# cslr_dmac5501_001 register map
Vendor: Texas Instruments
Peripheral module from a debugger description file.
Registers are 16-bit, read-write, reset 0x0 unless marked. A register's access mark holds for its fields unless they carry their own. Offsets are as the file gives them; lines under a group give offsets from that group; [hi:lo] are bit positions; {n}, {i} and the like mark numbered series; 'fields as' and 'values as' point back to an identical list; <NAME> marks a mode.

## DMA — Direct Memory Access
0x00 DMAGCR access per field — Global Control Register
  [2] FREE rw — Emulation mode bit.
    0=A breakpoint suspends DMA transfers; 1=DMA transfers continue uninterrupted when a breakpoint occurs
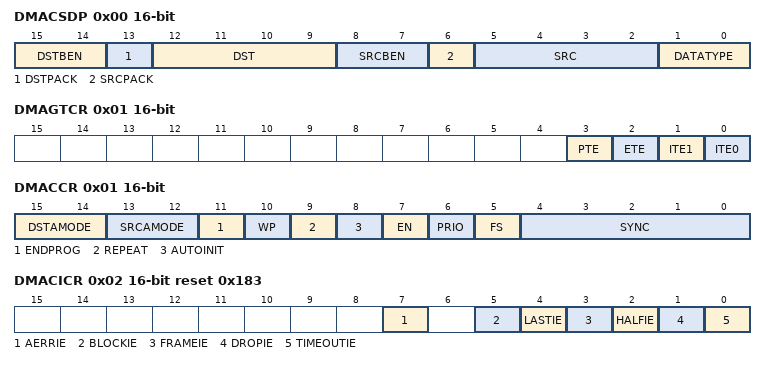
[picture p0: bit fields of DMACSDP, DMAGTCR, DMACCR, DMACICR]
0x00 DMACSDP — Source and Destination Parameters Register
  [15:14] DSTBEN — Destination burst enable bit.
    0=Bursting disabled (single access enabled) at the destination; 1=Bursting disabled (single access enabled) at the destination; 2=Bursting enabled at the destination
  [13] DSTPACK — Destination packing enable bit.
    0=Packing disabled at the destination; 1=Packing enabled at the destination
  [12:9] DST — Destination selection bit.
    0=DARAM via internal memory port 0; 1=DARAM via internal memory port 1; 2=External memory via the external memory interface (EMIF); 3=Peripherals via the peripheral bus controller
  [8:7] SRCBEN — Source burst enable bit.
    0=Bursting disabled (single access enabled) at the source; 1=Bursting disabled (single access enabled) at the source; 2=Bursting enabled at the source
  [6] SRCPACK — Source packing enable bit.
    0=Packing disabled at the source; 1=Packing enabled at the source
  [5:2] SRC — Source selection bit.
    values as DST
  [1:0] DATATYPE — Data type bit.
    0=8-bit; 1=16-bit; 2=32-bit
0x01 DMAGTCR access per field — Global Time-Out Control Register
  [all] fields
    0=Time-out counter disabled; 1=Time-out counter enabled
  [3] PTE rw — Peripheral port time-out counter enable bit.
  [2] ETE rw — External memory port time-out counter enable bit.
  [1] ITE1 rw — Internal memory port 1 time-out counter enable bit.
  [0] ITE0 rw — Internal memory port 0 time-out counter enable bit.
0x01 DMACCR — Channel Control Register
  [15:14] DSTAMODE — Destination addressing mode.
    0=Constant address; 1=Automatic post increment; 2=Single index; 3=Double index (sort)
  [13:12] SRCAMODE — Source addressing mode.
    values as DSTAMODE
  [11] ENDPROG — End-of-programming bit.
    0=Configuration registers ready for programming / Programming in progress; 1=End of programming
  [10] WP — Write posting bit.
    0=Write posting disabled; 1=Write posting enabled
  [9] REPEAT — Repeat condition bit. If auto-initialization is selected for a channel (AUTOINIT = 1), REPEAT specifies one of two special repeat conditions
    0=Repeat only if ENDPROG = 1; 1=Repeat regardless of ENDPROG
  [8] AUTOINIT — Auto-initialization bit.
    0=Auto-initialization is disabled; 1=Auto-initialization is enabled
  [7] EN — Channel enable bit.
    0=Channel is disabled; 1=Channel is enabled
  [6] PRIO — Channel priority bit.
    0=Low priority; 1=High priority
  [5] FS — Frame/element synchronization bit.
    0=Element synchronization; 1=Frame synchronization
  [4:0] SYNC — Synchronization control bits.
    0=No synchronization event; 1=McBSP 0 receive event; 2=McBSP 0 transmit event; 5=McBSP 1 receive event; 6=McBSP 1 transmit event; 9=Reserved/McBSP event; 10=Reserved/McBSP event; 11=Reserved/UART event; 12=Reserved/UART event; 13=Timer 0 interrupt event; 14=Timer 1 interrupt event; {v}=External interrupt {v-15} (v=15..18); 19=I2C module receive event; 20=I2C module transmit event
0x02 DMACICR access per field reset 0x183 — Interrupt Control Register
  [all] fields
    0=Do not send the channel interrupt request to the CPU when this error occurs; 1=Send the channel interrupt request to the CPU when this error occurs
  [7] AERRIE rw — Address error interrupt enable bit.
  [5] BLOCKIE rw — Whole block interrupt enable bit.
  [4] LASTIE rw — Last frame interrupt enable bit.
  [3] FRAMEIE rw — Whole frame interrupt enable bit.
  [2] HALFIE rw — Half frame interrupt enable bit.
  [1] DROPIE rw — Synchronization event drop interrupt enable bit.
  [0] TIMEOUTIE rw — Time-out interrupt enable bit.
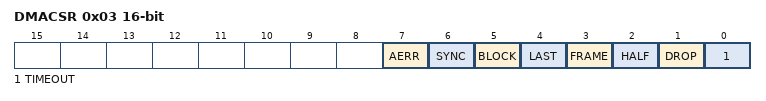
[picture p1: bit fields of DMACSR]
0x03 DMACSR ro — Status Register
  [7] AERR — Address error status bit.
    0=An address error has not occurred, or AERR has been cleared; 1=An address error has occurred
  [6] SYNC — Synchronization event status bit.
    0=The DMA controller has finished servicing the previous access request; 1=The synchronization event has occurred
  [5] BLOCK — Whole block status bit.
    0=The whole-block event has not occurred yet, or BLOCK has been cleared; 1=The whole block has been transferred
  [4] LAST — Last frame status bit.
    0=The last-frame event has not occurred yet, or LAST has been cleared; 1=The DMA controller has started transferring the last frame
  [3] FRAME — Whole frame status bit.
    0=The whole-frame event has not occurred yet, or FRAME has been cleared; 1=The whole frame has been transferred
  [2] HALF — Half frame status bit.
    0=The half-frame event has not occurred yet, or HALF has been cleared; 1=The first half of the frame has been transferred
  [1] DROP — Synchronization event drop status bit.
    0=A synchronization event drop has not occurred, or DROP has been cleared; 1=A synchronization event drop has occurred
  [0] TIMEOUT — Time-out status bit.
    0=A time-out error has not occurred, or TIMEOUT has been cleared; 1=A time-out error has occurred
0x04 DMACSSAL — Source Start Address Registers
  [15:0] SSAL — Lower part of source start address (byte address)
0x05 DMACSSAU — Source Start Address Registers
  [15:0] SSAU — Upper part of source start address (byte address)
0x06 DMACDSAL — Destination Start Address Registers
  [15:0] DSAL — Lower part of destination start address (byte address)
0x07 DMACDSAU — Destination Start Address Registers
  [15:0] DSAU
0x08 DMACEN reset 0x1 — Element Number Register
  [15:0] ELEMENTNUM
0x09 DMACFN reset 0x1 — Frame Number Register
  [15:0] FRAMENUM
0x0A DMACSFI — Frame Index Registers
  [15:0] FRAMENDX — Source frame index (in bytes)
0x0B DMACSEI — Element Index Registers
  [15:0] ELEMENTNDX — Source element index (in bytes)
0x0C DMACSAC — Source Address Counter
  [15:0] SAC — Current channel source address
0x0D DMACDAC — Destination Address Counter
  [15:0] DAC — Current channel destination address
0x0E DMACDEI — Element Index Registers
  [15:0] ELEMENTNDX — Destination element index (in bytes)
0x0F DMACDFI — Frame Index Registers
  [15:0] FRAMENDX — Destination frame index (in bytes)
